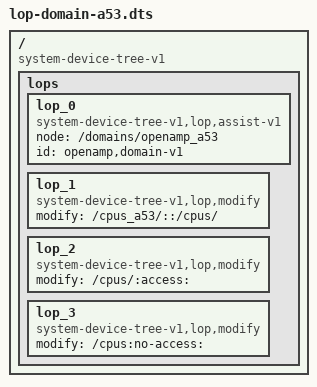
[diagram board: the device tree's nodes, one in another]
/*
 * Copyright (c) 2019,2020 Xilinx Inc. All rights reserved.
 *
 * Author:
 *       Bruce Ashfield <bruce.ashfield@xilinx.com>
 *
 * SPDX-License-Identifier: BSD-3-Clause
 */

/dts-v1/;

/ {
        compatible = "system-device-tree-v1";
        lops {
                // compatible = "system-device-tree-v1,lop";
                lop_0 {
                        compatible = "system-device-tree-v1,lop,assist-v1";
                        node = "/domains/openamp_a53";
                        id = "openamp,domain-v1";
                };
                lop_1 {
                        // node name modify
                        compatible = "system-device-tree-v1,lop,modify";
                        modify = "/cpus_a53/::/cpus/";
                };
                lop_2 {
                        compatible = "system-device-tree-v1,lop,modify";
                        // format is: "path":"property":"replacement"
                        //    - modify to "nothing", is a remove operation
                        //    - modify with no property is node operation (rename or remove)
                        modify = "/cpus/:access:";
                };
                lop_3 {
                        // modify to "nothing", is a remove operation
                        compatible = "system-device-tree-v1,lop,modify";
                        modify = "/cpus:no-access:";
                };
        };
};
